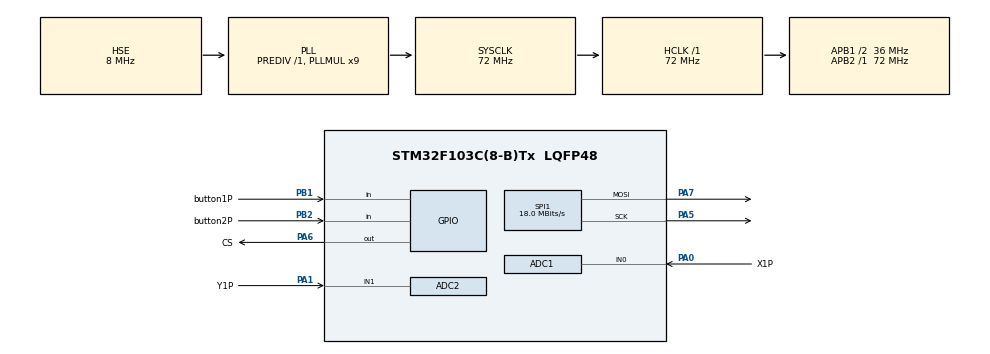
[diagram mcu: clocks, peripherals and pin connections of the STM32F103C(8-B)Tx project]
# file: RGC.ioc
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ADC1.Channel-0\#ChannelRegularConversion=ADC_CHANNEL_0
ADC1.NbrOfConversionFlag=1
ADC1.Rank-0\#ChannelRegularConversion=1
ADC1.SamplingTime-0\#ChannelRegularConversion=ADC_SAMPLETIME_1CYCLE_5
ADC1.master=1
ADC2.Channel-0\#ChannelRegularConversion=ADC_CHANNEL_1
ADC2.NbrOfConversionFlag=1
ADC2.Rank-0\#ChannelRegularConversion=1
ADC2.SamplingTime-0\#ChannelRegularConversion=ADC_SAMPLETIME_1CYCLE_5
Mcu.Family=STM32F1
Mcu.Name=STM32F103C(8-B)Tx
Mcu.Package=LQFP48
NVIC.ADC1_2_IRQn=true\:0\:0\:false\:false\:true\:true\:true
NVIC.PriorityGroup=NVIC_PRIORITYGROUP_4
PA0-WKUP.GPIO_Label=X1P
PA0-WKUP.Signal=ADCx_IN0
PA1.GPIO_Label=Y1P
PA1.Signal=ADCx_IN1
PA13.Mode=Serial_Wire
PA13.Signal=SYS_JTMS-SWDIO
PA14.Mode=Serial_Wire
PA14.Signal=SYS_JTCK-SWCLK
PA5.Mode=TX_Only_Simplex_Unidirect_Master
PA5.Signal=SPI1_SCK
PA6.GPIO_Label=CS
PA6.Signal=GPIO_Output
PA7.Mode=TX_Only_Simplex_Unidirect_Master
PA7.Signal=SPI1_MOSI
PB1.GPIO_Label=button1P
PB1.GPIO_PuPd=GPIO_PULLUP
PB1.Signal=GPIO_Input
PB2.GPIO_Label=button2P
PB2.GPIO_PuPd=GPIO_PULLUP
PB2.Signal=GPIO_Input
PD0-OSC_IN.Mode=HSE-External-Oscillator
PD0-OSC_IN.Signal=RCC_OSC_IN
PD1-OSC_OUT.Mode=HSE-External-Oscillator
PD1-OSC_OUT.Signal=RCC_OSC_OUT
ProjectManager.HeapSize=0x200
ProjectManager.StackSize=0x400
ProjectManager.TargetToolchain=STM32CubeIDE
RCC.ADCPresc=RCC_ADCPCLK2_DIV6
RCC.AHBFreq_Value=72000000
RCC.APB1CLKDivider=RCC_HCLK_DIV2
RCC.APB1Freq_Value=36000000
RCC.APB1TimFreq_Value=72000000
RCC.APB2Freq_Value=72000000
RCC.APB2TimFreq_Value=72000000
RCC.HCLKFreq_Value=72000000
RCC.PLLMUL=RCC_PLL_MUL9
RCC.PLLSourceVirtual=RCC_PLLSOURCE_HSE
RCC.SYSCLKFreq_VALUE=72000000
RCC.SYSCLKSource=RCC_SYSCLKSOURCE_PLLCLK
RCC.USBFreq_Value=72000000
SH.ADCx_IN0.0=ADC1_IN0,IN0
SH.ADCx_IN1.0=ADC2_IN1,IN1
SPI1.BaudRatePrescaler=SPI_BAUDRATEPRESCALER_4
SPI1.CalculateBaudRate=18.0 MBits/s
SPI1.Direction=SPI_DIRECTION_2LINES
SPI1.Mode=SPI_MODE_MASTER
SPI1.VirtualType=VM_MASTER
board=custom

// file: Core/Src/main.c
/* USER CODE BEGIN Header */
/**
  ******************************************************************************
  * @file           : main.c
  * @brief          : Main program body
  ******************************************************************************
  * @attention
  *
  * <h2><center>&copy; Copyright (c) 2020 STMicroelectronics.
  * All rights reserved.</center></h2>
  *
  * This software component is licensed by ST under BSD 3-Clause license,
  * the "License"; You may not use this file except in compliance with the
  * License. You may obtain a copy of the License at:
  *                        opensource.org/licenses/BSD-3-Clause
  *
  ******************************************************************************
  */
/* USER CODE END Header */

#include "main.h"
#include "adc.h"
#include "spi.h"
#include "gpio.h"

void SystemClock_Config(void);

int main(void)
{

  /* MCU Configuration--------------------------------------------------------*/

  /* Reset of all peripherals, Initializes the Flash interface and the Systick. */
  HAL_Init();

  /* Configure the system clock */
  SystemClock_Config();

  /* Initialize all configured peripherals */
  MX_GPIO_Init();
  MX_ADC1_Init();
  MX_ADC2_Init();
  MX_SPI1_Init();
  /* USER CODE BEGIN 2 */
  matrixSetup(5, 6);

  setLEDM(12, 13, true, true);

  clearAllDisplay();
  SnakeSetup();
  /* USER CODE END 2 */

  /* Infinite loop */
  /* USER CODE BEGIN WHILE */
  while (1)
  {
	  SnakeLoop();
    /* USER CODE END WHILE */

  }
}

void SystemClock_Config(void)
{
  RCC_OscInitTypeDef RCC_OscInitStruct = {0};
  RCC_ClkInitTypeDef RCC_ClkInitStruct = {0};
  RCC_PeriphCLKInitTypeDef PeriphClkInit = {0};

  /** Initializes the CPU, AHB and APB busses clocks
  */
  RCC_OscInitStruct.OscillatorType = RCC_OSCILLATORTYPE_HSE;
  RCC_OscInitStruct.HSEState = RCC_HSE_ON;
  RCC_OscInitStruct.HSEPredivValue = RCC_HSE_PREDIV_DIV1;
  RCC_OscInitStruct.HSIState = RCC_HSI_ON;
  RCC_OscInitStruct.PLL.PLLState = RCC_PLL_ON;
  RCC_OscInitStruct.PLL.PLLSource = RCC_PLLSOURCE_HSE;
  RCC_OscInitStruct.PLL.PLLMUL = RCC_PLL_MUL9;
  if (HAL_RCC_OscConfig(&RCC_OscInitStruct) != HAL_OK)
  {
    Error_Handler();
  }
  /** Initializes the CPU, AHB and APB busses clocks
  */
  RCC_ClkInitStruct.ClockType = RCC_CLOCKTYPE_HCLK|RCC_CLOCKTYPE_SYSCLK
                              |RCC_CLOCKTYPE_PCLK1|RCC_CLOCKTYPE_PCLK2;
  RCC_ClkInitStruct.SYSCLKSource = RCC_SYSCLKSOURCE_PLLCLK;
  RCC_ClkInitStruct.AHBCLKDivider = RCC_SYSCLK_DIV1;
  RCC_ClkInitStruct.APB1CLKDivider = RCC_HCLK_DIV2;
  RCC_ClkInitStruct.APB2CLKDivider = RCC_HCLK_DIV1;

  if (HAL_RCC_ClockConfig(&RCC_ClkInitStruct, FLASH_LATENCY_2) != HAL_OK)
  {
    Error_Handler();
  }
  PeriphClkInit.PeriphClockSelection = RCC_PERIPHCLK_ADC;
  PeriphClkInit.AdcClockSelection = RCC_ADCPCLK2_DIV6;
  if (HAL_RCCEx_PeriphCLKConfig(&PeriphClkInit) != HAL_OK)
  {
    Error_Handler();
  }
}

void Error_Handler(void)
{
}

/************************ (C) COPYRIGHT STMicroelectronics *****END OF FILE****/
